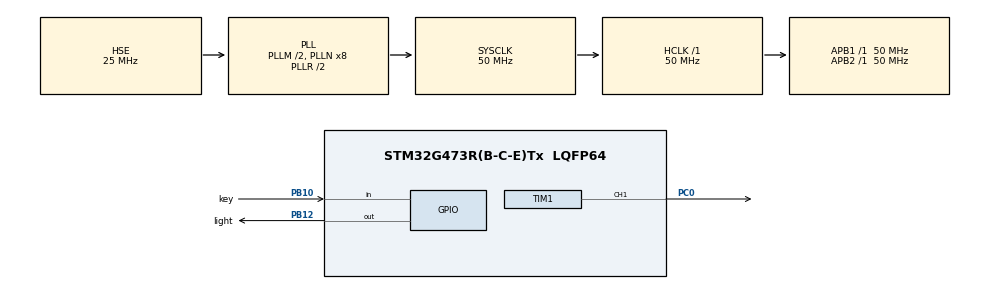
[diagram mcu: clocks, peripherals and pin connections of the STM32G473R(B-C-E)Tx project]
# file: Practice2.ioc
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Mcu.Family=STM32G4
Mcu.Name=STM32G473R(B-C-E)Tx
Mcu.Package=LQFP64
NVIC.PriorityGroup=NVIC_PRIORITYGROUP_4
NVIC.TIM1_BRK_TIM15_IRQn=true\:0\:0\:false\:false\:true\:true\:true\:true
NVIC.TIM4_IRQn=true\:0\:0\:false\:false\:true\:true\:true\:true
PA13.Mode=Serial_Wire
PA13.Signal=SYS_JTMS-SWDIO
PA14.Mode=Serial_Wire
PA14.Signal=SYS_JTCK-SWCLK
PA6.Signal=EVENTOUT
PB10.GPIO_Label=key
PB10.GPIO_PuPd=GPIO_PULLUP
PB10.Signal=GPIO_Input
PB12.GPIO_Label=light
PB12.PinState=GPIO_PIN_RESET
PB12.Signal=GPIO_Output
PC0.Signal=S_TIM1_CH1
PF0-OSC_IN.Mode=HSE-External-Oscillator
PF0-OSC_IN.Signal=RCC_OSC_IN
PF1-OSC_OUT.Mode=HSE-External-Oscillator
PF1-OSC_OUT.Signal=RCC_OSC_OUT
ProjectManager.HeapSize=0x200
ProjectManager.StackSize=0x400
ProjectManager.TargetToolchain=CMake
RCC.ADC12Freq_Value=50000000
RCC.ADC345Freq_Value=50000000
RCC.AHBFreq_Value=50000000
RCC.APB1Freq_Value=50000000
RCC.APB1TimFreq_Value=50000000
RCC.APB2Freq_Value=50000000
RCC.APB2TimFreq_Value=50000000
RCC.CortexFreq_Value=50000000
RCC.EXTERNAL_CLOCK_VALUE=12288000
RCC.HCLKFreq_Value=50000000
RCC.HSE_VALUE=25000000
RCC.HSI48_VALUE=48000000
RCC.HSI_VALUE=16000000
RCC.LSE_VALUE=32768
RCC.PLLM=RCC_PLLM_DIV2
RCC.PLLSourceVirtual=RCC_PLLSOURCE_HSE
RCC.SYSCLKFreq_VALUE=50000000
RCC.SYSCLKSource=RCC_SYSCLKSOURCE_PLLCLK
RCC.USBFreq_Value=50000000
RCC.VCOOutputFreq_Value=100000000
SH.S_TIM1_CH1.0=TIM1_CH1,PWM Generation1 CH1
TIM1.Channel-PWM\ Generation1\ CH1=TIM_CHANNEL_1
TIM1.PeriodNoDither=2999
TIM1.Prescaler=49
TIM4.PeriodNoDither=999
TIM4.Prescaler=49
VP_SYS_VS_DBSignals.Mode=DisableDeadBatterySignals
VP_TIM1_VS_ClockSourceINT.Mode=Internal
VP_TIM4_VS_ClockSourceINT.Mode=Internal
board=custom

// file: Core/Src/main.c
/* USER CODE BEGIN Header */
/**
  ******************************************************************************
  * @file           : main.c
  * @brief          : Main program body
  ******************************************************************************
  * @attention
  *
  * Copyright (c) 2026 STMicroelectronics.
  * All rights reserved.
  *
  * This software is licensed under terms that can be found in the LICENSE file
  * in the root directory of this software component.
  * If no LICENSE file comes with this software, it is provided AS-IS.
  *
  ******************************************************************************
  */
/* USER CODE END Header */
#include "main.h"
#include "tim.h"
#include "gpio.h"

/* USER CODE BEGIN PV */
uint16_t count = 0;
uint8_t zt =0; /*状态（？）*/
uint8_t st =1; /*时态（？）*/
uint16_t loc =1500; /*location*/
uint16_t count2 =0;
uint16_t rank =0;
uint16_t jiange =0;
uint8_t keysta =0;
uint8_t on =1;
uint8_t cksta;
/* USER CODE END PV */

void SystemClock_Config(void);

int main(void)
{

  /* MCU Configuration--------------------------------------------------------*/

  /* Reset of all peripherals, Initializes the Flash interface and the Systick. */
  HAL_Init();

  /* Configure the system clock */
  SystemClock_Config();

  /* Initialize all configured peripherals */
  MX_GPIO_Init();
  MX_TIM4_Init();
  MX_TIM1_Init();
  /* USER CODE BEGIN 2 */
HAL_TIM_Base_Start_IT(&htim4);
  HAL_TIM_PWM_Start(&htim1, TIM_CHANNEL_1);
  __HAL_TIM_MOE_ENABLE(&htim1);
  __HAL_TIM_SetCompare(&htim1, TIM_CHANNEL_1, 1500);
  /* USER CODE END 2 */

  /* Infinite loop */
  while (1)
  {

  }
}

void SystemClock_Config(void)
{
  RCC_OscInitTypeDef RCC_OscInitStruct = {0};
  RCC_ClkInitTypeDef RCC_ClkInitStruct = {0};

  /** Configure the main internal regulator output voltage
  */
  HAL_PWREx_ControlVoltageScaling(PWR_REGULATOR_VOLTAGE_SCALE1);

  /** Initializes the RCC Oscillators according to the specified parameters
  * in the RCC_OscInitTypeDef structure.
  */
  RCC_OscInitStruct.OscillatorType = RCC_OSCILLATORTYPE_HSE;
  RCC_OscInitStruct.HSEState = RCC_HSE_ON;
  RCC_OscInitStruct.PLL.PLLState = RCC_PLL_ON;
  RCC_OscInitStruct.PLL.PLLSource = RCC_PLLSOURCE_HSE;
  RCC_OscInitStruct.PLL.PLLM = RCC_PLLM_DIV2;
  RCC_OscInitStruct.PLL.PLLN = 8;
  RCC_OscInitStruct.PLL.PLLP = RCC_PLLP_DIV2;
  RCC_OscInitStruct.PLL.PLLQ = RCC_PLLQ_DIV2;
  RCC_OscInitStruct.PLL.PLLR = RCC_PLLR_DIV2;
  if (HAL_RCC_OscConfig(&RCC_OscInitStruct) != HAL_OK)
  {
    Error_Handler();
  }

  /** Initializes the CPU, AHB and APB buses clocks
  */
  RCC_ClkInitStruct.ClockType = RCC_CLOCKTYPE_HCLK|RCC_CLOCKTYPE_SYSCLK
                              |RCC_CLOCKTYPE_PCLK1|RCC_CLOCKTYPE_PCLK2;
  RCC_ClkInitStruct.SYSCLKSource = RCC_SYSCLKSOURCE_PLLCLK;
  RCC_ClkInitStruct.AHBCLKDivider = RCC_SYSCLK_DIV1;
  RCC_ClkInitStruct.APB1CLKDivider = RCC_HCLK_DIV1;
  RCC_ClkInitStruct.APB2CLKDivider = RCC_HCLK_DIV1;

  if (HAL_RCC_ClockConfig(&RCC_ClkInitStruct, FLASH_LATENCY_1) != HAL_OK)
  {
    Error_Handler();
  }
}

/* USER CODE BEGIN 4 */
void HAL_TIM_PeriodElapsedCallback(TIM_HandleTypeDef *htim)
{
  if (htim==&htim4)
  {
    cksta=HAL_GPIO_ReadPin(key_GPIO_Port,key_Pin);
    switch (keysta)
    {
    case 0:
      if (cksta==0)
      {
        keysta=1;
        jiange=1;
      }
      break;
    case 1:
      if (cksta==0)
      {
        jiange++;
        if (jiange >= 1000)
        {
          on=!on;
          keysta=0;
        }
      }
      else
      {
        if (jiange < 300)
        {
          keysta=2;
          jiange =0;
        }
        else{keysta =0;}
      }
      break;
    case 2:
      jiange++;
      if (cksta == 0)
      {
        rank++;
        if (rank>2) rank=0;
        keysta=0;
      }
      else if (jiange >300)
      {
        st++;
        if (st>3) st=1;
        keysta=0;
      }
      break;
    }
    if (on==1){
      count++;
      if (count >= 500/(st))
      {
        count = 0;
        HAL_GPIO_TogglePin(light_GPIO_Port,light_Pin);
        if (zt==0)
        {
          loc=2500-rank*300;
          zt=1;
        }
        else
        {
          loc=500+rank*300;
          zt=0;
        }
        __HAL_TIM_SetCompare(&htim1,TIM_CHANNEL_1,loc);

      }
    }
  }
}

/* USER CODE END 4 */

void Error_Handler(void)
{
  __disable_irq();
  while (1)
  {
  }
}
